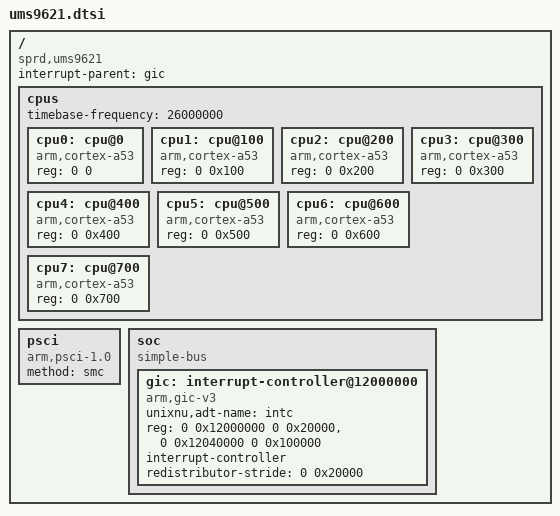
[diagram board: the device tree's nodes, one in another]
// SPDX-License-Identifier: BSD-3-Clause
// Unisoc UMS9621 SoC: 8x Cortex-A53, GICv3, PSCI smc, 26 MHz arch timer.
/ {
    compatible = "sprd,ums9621";
    #address-cells = <2>;
    #size-cells = <2>;
    interrupt-parent = <&gic>;

    cpus {
        #address-cells = <2>;
        #size-cells = <0>;
        timebase-frequency = <26000000>;
        cpu0: cpu@0 { device_type = "cpu"; compatible = "arm,cortex-a53"; reg = <0 0>; };
        cpu1: cpu@100 { device_type = "cpu"; compatible = "arm,cortex-a53"; reg = <0 0x100>; };
        cpu2: cpu@200 { device_type = "cpu"; compatible = "arm,cortex-a53"; reg = <0 0x200>; };
        cpu3: cpu@300 { device_type = "cpu"; compatible = "arm,cortex-a53"; reg = <0 0x300>; };
        cpu4: cpu@400 { device_type = "cpu"; compatible = "arm,cortex-a53"; reg = <0 0x400>; };
        cpu5: cpu@500 { device_type = "cpu"; compatible = "arm,cortex-a53"; reg = <0 0x500>; };
        cpu6: cpu@600 { device_type = "cpu"; compatible = "arm,cortex-a53"; reg = <0 0x600>; };
        cpu7: cpu@700 { device_type = "cpu"; compatible = "arm,cortex-a53"; reg = <0 0x700>; };
    };

    psci {
        compatible = "arm,psci-1.0", "arm,psci-0.2";
        method = "smc";
    };

    soc {
        compatible = "simple-bus";
        #address-cells = <2>;
        #size-cells = <2>;
        ranges;

        gic: interrupt-controller@12000000 {
            compatible = "arm,gic-v3";
            unixnu,adt-name = "intc";
            reg = <0 0x12000000 0 0x20000>, <0 0x12040000 0 0x100000>;
            #interrupt-cells = <4>;
            #address-cells = <0>;
            interrupt-controller;
            redistributor-stride = <0 0x20000>;
        };
    };
};
